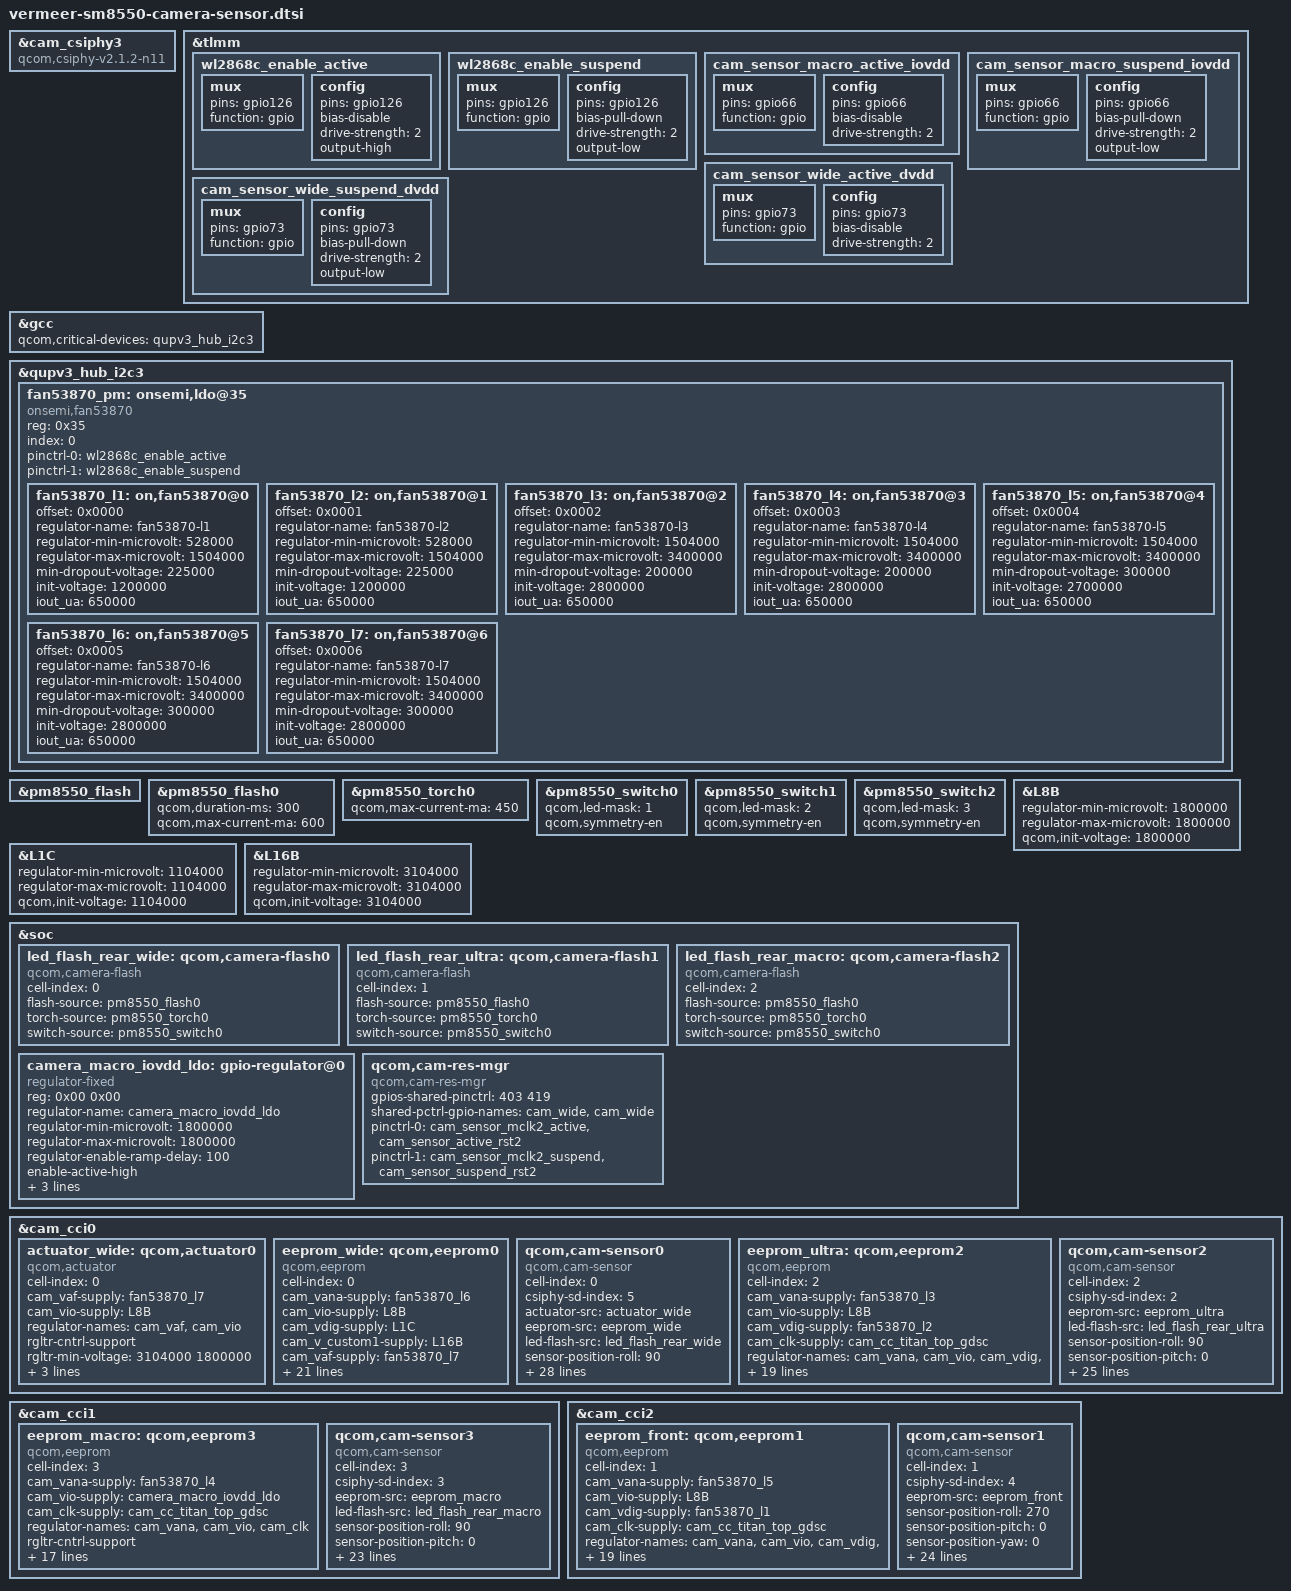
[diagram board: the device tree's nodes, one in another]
#include <dt-bindings/msm-camera.h>

//macro
&cam_csiphy3 {
	compatible = "qcom,csiphy-v2.1.2-n11", "qcom,csiphy";
};

&tlmm {
	wl2868c_enable_active: wl2868c_enable_active {
		mux {
				pins = "gpio126";
				function = "gpio";
		};

		config {
				pins = "gpio126";
				bias-disable;
				drive-strength = <2>;
				output-high;
		};
	};

	wl2868c_enable_suspend: wl2868c_enable_suspend {
		mux {
				pins = "gpio126";
				function = "gpio";
		};

		config {
				pins = "gpio126";
				bias-pull-down;
				drive-strength = <2>;
				output-low;
		};
	};

	cam_sensor_macro_active_iovdd: cam_sensor_macro_active_iovdd {
		mux {
			pins = "gpio66";
			function = "gpio";
		};

		config {
			pins = "gpio66";
			bias-disable; /* No PULL */
			drive-strength = <2>; /* 2 MA */
		};
	};

	cam_sensor_macro_suspend_iovdd: cam_sensor_macro_suspend_iovdd {
		mux {
			pins = "gpio66";
			function = "gpio";
		};

		config {
			pins = "gpio66";
			bias-pull-down; /* PULL DOWN */
			drive-strength = <2>; /* 2 MA */
			output-low;
		};
	};

	cam_sensor_wide_active_dvdd: cam_sensor_wide_active_dvdd {
		mux {
			pins = "gpio73";
			function = "gpio";
		};

		config {
			pins = "gpio73";
			bias-disable; /* No PULL */
			drive-strength = <2>; /* 2 MA */
		};
	};

	cam_sensor_wide_suspend_dvdd: cam_sensor_wide_suspend_dvdd {
		mux {
			pins = "gpio73";
			function = "gpio";
		};

		config {
			pins = "gpio73";
			bias-pull-down; /* PULL DOWN */
			drive-strength = <2>; /* 2 MA */
			output-low;
		};
	};
};

&gcc {
	qcom,critical-devices = <&qupv3_hub_i2c3>;
};

&qupv3_hub_i2c3 {
	#address-cells = <1>;
	#size-cells = <0>;
	status = "ok";

	fan53870_pm:onsemi,ldo@35 {
		compatible = "onsemi,fan53870";
		reg = <0x35>;/*slave address*/
		index = <0>;
		pinctrl-names = "wl2868c_enable", "wl2868c_disable";
		pinctrl-0 = <&wl2868c_enable_active>;
		pinctrl-1 = <&wl2868c_enable_suspend>;

		fan53870_l1:on,fan53870@0{
			offset = /bits/ 16 <0x0000>;
			regulator-name ="fan53870-l1";
			regulator-min-microvolt = <528000>;
			regulator-max-microvolt = <1504000>;
			min-dropout-voltage = <225000>;
			init-voltage = <1200000>;
			iout_ua = <650000>;
		};

		fan53870_l2:on,fan53870@1{
			offset = /bits/ 16 <0x0001>;
			regulator-name ="fan53870-l2";
			regulator-min-microvolt = <528000>;
			regulator-max-microvolt = <1504000>;
			min-dropout-voltage = <225000>;
			init-voltage = <1200000>;
			iout_ua = <650000>;
		};

		fan53870_l3:on,fan53870@2{
			offset = /bits/ 16 <0x0002>;
			regulator-name ="fan53870-l3";
			regulator-min-microvolt = <1504000>;
			regulator-max-microvolt = <3400000>;
			min-dropout-voltage = <200000>;
			init-voltage = <2800000>;
			iout_ua = <650000>;
		};

		fan53870_l4:on,fan53870@3{
			offset = /bits/ 16 <0x0003>;
			regulator-name ="fan53870-l4";
			regulator-min-microvolt = <1504000>;
			regulator-max-microvolt = <3400000>;
			min-dropout-voltage = <200000>;
			init-voltage = <2800000>;
			iout_ua = <650000>;
		};

		fan53870_l5:on,fan53870@4{
			offset = /bits/ 16 <0x0004>;
			regulator-name ="fan53870-l5";
			regulator-min-microvolt = <1504000>;
			regulator-max-microvolt = <3400000>;
			min-dropout-voltage = <300000>;
			init-voltage = <2700000>;
			iout_ua = <650000>;
		};

		fan53870_l6:on,fan53870@5{
			offset = /bits/ 16 <0x0005>;
			regulator-name ="fan53870-l6";
			regulator-min-microvolt = <1504000>;
			regulator-max-microvolt = <3400000>;
			min-dropout-voltage = <300000>;
			init-voltage = <2800000>;
			iout_ua = <650000>;
		};

		fan53870_l7:on,fan53870@6{
			offset = /bits/ 16 <0x0006>;
			regulator-name ="fan53870-l7";
			regulator-min-microvolt = <1504000>;
			regulator-max-microvolt = <3400000>;
			min-dropout-voltage = <300000>;
			init-voltage = <2800000>;
			iout_ua = <650000>;
		};
	};
};

&pm8550_flash {
	status = "ok";
};
&pm8550_flash0 {
	qcom,duration-ms = <300>;
	qcom,max-current-ma = <600>;
};
&pm8550_torch0{
	qcom,max-current-ma = <450>;
};
&pm8550_switch0 {
	qcom,led-mask = <1>;
	qcom,symmetry-en;
};
&pm8550_switch1 {
	qcom,led-mask = <2>;
	qcom,symmetry-en;
};
&pm8550_switch2 {
	qcom,led-mask = <3>;
	qcom,symmetry-en;
};

&L8B {
	regulator-min-microvolt = <1800000>;
	regulator-max-microvolt = <1800000>;
	qcom,init-voltage = <1800000>;
};

&L1C {
	regulator-min-microvolt = <1104000>;
	regulator-max-microvolt = <1104000>;
	qcom,init-voltage = <1104000>;
};

&L16B {
	regulator-min-microvolt = <3104000>;
	regulator-max-microvolt = <3104000>;
	qcom,init-voltage = <3104000>;
};

&soc {
	led_flash_rear_wide: qcom,camera-flash0 {
		cell-index = <0>;
		compatible = "qcom,camera-flash";
		flash-source = <&pm8550_flash0>;
		torch-source = <&pm8550_torch0>;
		switch-source = <&pm8550_switch0>;
		status = "ok";
	};

	led_flash_rear_ultra: qcom,camera-flash1 {
		cell-index = <1>;
		compatible = "qcom,camera-flash";
		flash-source = <&pm8550_flash0>;
		torch-source = <&pm8550_torch0>;
		switch-source = <&pm8550_switch0>;
		status = "ok";
	};

	led_flash_rear_macro: qcom,camera-flash2 {
		cell-index = <2>;
		compatible = "qcom,camera-flash";
		flash-source = <&pm8550_flash0>;
		torch-source = <&pm8550_torch0>;
		switch-source = <&pm8550_switch0>;
		status = "ok";
	};

	camera_macro_iovdd_ldo: gpio-regulator@0 {
		compatible = "regulator-fixed";
		reg = <0x00 0x00>;
		regulator-name = "camera_macro_iovdd_ldo";
		regulator-min-microvolt = <1800000>;
		regulator-max-microvolt = <1800000>;
		regulator-enable-ramp-delay = <100>;
		enable-active-high;
		gpio = <&tlmm 66 0>;
		pinctrl-names = "macro_iovdd_active", "macro_iovdd_suspend";
		pinctrl-0 = <&cam_sensor_macro_active_iovdd
					 &cam_sensor_macro_suspend_iovdd>;
	};
/*P0的bom，下面的LDO没有贴
	camera_wide_dvdd_ldo: gpio-regulator@1 {
		compatible = "regulator-fixed";
		reg = <0x01 0x00>;
		regulator-name = "camera_wide_dvdd_ldo";
		regulator-min-microvolt = <1104000>;
		regulator-max-microvolt = <1104000>;
		regulator-enable-ramp-delay = <100>;
		enable-active-high;
		gpio = <&tlmm 73 0>;
		pinctrl-names = "wide_dvdd_active", "wide_dvdd_suspend";
		pinctrl-0 = <&cam_sensor_wide_active_dvdd
					 &cam_sensor_wide_suspend_dvdd>;
	};
*/
	qcom,cam-res-mgr {
		compatible = "qcom,cam-res-mgr";
		gpios-shared-pinctrl = <403 419>;
		shared-pctrl-gpio-names = "cam_wide", "cam_wide";
		pinctrl-names = "cam_wide_active", "cam_wide_suspend";
		pinctrl-0 = <&cam_sensor_mclk2_active
					 &cam_sensor_active_rst2>;
		pinctrl-1 = <&cam_sensor_mclk2_suspend
					 &cam_sensor_suspend_rst2>;
		status = "ok";
	};
};

&cam_cci0 {

	actuator_wide: qcom,actuator0 {
		cell-index = <0>;
		compatible = "qcom,actuator";
		cam_vaf-supply = <&fan53870_l7>;
		cam_vio-supply = <&L8B>;
		regulator-names = "cam_vaf", "cam_vio";
		rgltr-cntrl-support;
		rgltr-min-voltage = <3104000 1800000>;
		rgltr-max-voltage = <3104000 1800000>;
		rgltr-load-current = <120000 50000>;
		cci-master = <CCI_MASTER_0>;
		status = "ok";
	};

	eeprom_wide: qcom,eeprom0 {
		cell-index = <0>;
		compatible = "qcom,eeprom";
		cam_vana-supply = <&fan53870_l6>;
		cam_vio-supply = <&L8B>;
		cam_vdig-supply = <&L1C>;
		cam_v_custom1-supply = <&L16B>;//apois
		cam_vaf-supply = <&fan53870_l7>;
		cam_clk-supply = <&cam_cc_titan_top_gdsc>;
		regulator-names = "cam_vana", "cam_vio",
			"cam_vdig", "cam_v_custom1", "cam_vaf", "cam_clk";
		rgltr-cntrl-support;
		rgltr-min-voltage = <2800000 1800000 1104000 3104000 3104000 0>;
		rgltr-max-voltage = <2800000 1800000 1104000 3104000 3104000 0>;
		rgltr-load-current = <88000 50000 676300 310000 120000 0>;
		use-shared-clk;
		gpio-no-mux = <0>;
		gpios = <&tlmm 102 0>, <&tlmm 118 0>;
		gpio-reset = <1>;
		gpio-req-tbl-num = <0 1>;
		gpio-req-tbl-flags = <1 0>;
		gpio-req-tbl-label = "CAMIF_MCLK2", "CAM_RESET2";
		cci-master = <CCI_MASTER_0>;
		clocks = <&camcc CAM_CC_MCLK2_CLK>;
		clock-names = "cam_clk";
		clock-cntl-level = "nominal";
		clock-rates = <19200000>;
		status = "ok";
	};

	// wide sensor
	qcom,cam-sensor0 {
		cell-index = <0>;
		compatible = "qcom,cam-sensor";
		csiphy-sd-index = <5>;
		actuator-src = <&actuator_wide>;
		eeprom-src = <&eeprom_wide>;
		led-flash-src = <&led_flash_rear_wide>;
		sensor-position-roll = <90>;
		sensor-position-pitch = <0>;
		sensor-position-yaw = <180>;
		cam_vana-supply = <&fan53870_l6>;
		cam_vio-supply = <&L8B>;//ultra&front also use
		cam_vdig-supply = <&L1C>;//原理图内有两处供电，是基带做了兼容，基带建议使用L1C
		cam_v_custom1-supply = <&L16B>;//apois
		cam_vaf-supply = <&fan53870_l7>;
		cam_clk-supply = <&cam_cc_titan_top_gdsc>;
		regulator-names = "cam_vana", "cam_vio",
			"cam_vdig", "cam_v_custom1", "cam_vaf", "cam_clk";
		rgltr-cntrl-support;
		rgltr-min-voltage = <2800000 1800000 1104000 3104000 3104000 0>;
		rgltr-max-voltage = <2800000 1800000 1104000 3104000 3104000 0>;
		rgltr-load-current = <88000 50000 676300 310000 120000 0>;
		use-shared-clk;
		gpio-no-mux = <0>;
		gpios = <&tlmm 102 0>, <&tlmm 118 0>;
		gpio-reset = <1>;
		gpio-req-tbl-num = <0 1>;
		gpio-req-tbl-flags = <1 0>;
		gpio-req-tbl-label = "CAMIF_MCLK2", "CAM_RESET2";
		cci-master = <CCI_MASTER_0>;
		clocks = <&camcc CAM_CC_MCLK2_CLK>;
		clock-names = "cam_clk";
		clock-cntl-level = "nominal";
		clock-rates = <19200000>;
		status = "ok";
	};

	// Ultra eeprom
	eeprom_ultra: qcom,eeprom2 {
		cell-index = <2>;
		compatible = "qcom,eeprom";
		cam_vana-supply = <&fan53870_l3>;
		cam_vio-supply = <&L8B>;
		cam_vdig-supply = <&fan53870_l2>;
		cam_clk-supply = <&cam_cc_titan_top_gdsc>;
		regulator-names = "cam_vana", "cam_vio", "cam_vdig",
			 "cam_clk";
		rgltr-cntrl-support;
		rgltr-min-voltage = <2700000 1800000 1200000 0>;
		rgltr-max-voltage = <2700000 1800000 1200000 0>;
		rgltr-load-current = <23500 50000 75300 0>;
		gpio-no-mux = <0>;
		pinctrl-names = "cam_default", "cam_suspend";
		pinctrl-0 = <&cam_sensor_mclk1_active
			&cam_sensor_active_rst1>;
		pinctrl-1 = <&cam_sensor_mclk1_suspend
			&cam_sensor_suspend_rst1>;
		gpios = <&tlmm 101 0>, <&tlmm 117 0>;
		gpio-reset = <1>;
		gpio-req-tbl-num = <0 1>;
		gpio-req-tbl-flags = <1 0>;
		gpio-req-tbl-label = "CAMIF_MCLK1", "CAM_RESET1";
		cci-master = <CCI_MASTER_1>;
		clocks = <&camcc CAM_CC_MCLK1_CLK>;
		clock-names = "cam_clk";
		clock-cntl-level = "nominal";
		clock-rates = <19200000>;
		status = "ok";
	};

	// ultra sensor
	qcom,cam-sensor2 {
		cell-index = <2>;
		compatible = "qcom,cam-sensor";
		csiphy-sd-index = <2>;
		eeprom-src = <&eeprom_ultra>;
		led-flash-src = <&led_flash_rear_ultra>;
		sensor-position-roll = <90>;
		sensor-position-pitch = <0>;
		sensor-position-yaw = <180>;
		cam_vana-supply = <&fan53870_l3>;
		cam_vio-supply = <&L8B>;
		cam_vdig-supply = <&fan53870_l2>;
		cam_clk-supply = <&cam_cc_titan_top_gdsc>;
		regulator-names = "cam_vana", "cam_vio", "cam_vdig",
			 "cam_clk";
		rgltr-cntrl-support;
		rgltr-min-voltage = <2700000 1800000 1200000 0>;
		rgltr-max-voltage = <2700000 1800000 1200000 0>;
		rgltr-load-current = <23500 50000 75300 0>;
		gpio-no-mux = <0>;
		pinctrl-names = "cam_default", "cam_suspend";
		pinctrl-0 = <&cam_sensor_mclk1_active
			&cam_sensor_active_rst1>;
		pinctrl-1 = <&cam_sensor_mclk1_suspend
			&cam_sensor_suspend_rst1>;
		gpios = <&tlmm 101 0>, <&tlmm 117 0>;
		gpio-reset = <1>;
		gpio-req-tbl-num = <0 1>;
		gpio-req-tbl-flags = <1 0>;
		gpio-req-tbl-label = "CAMIF_MCLK1", "CAM_RESET1";
		cci-master = <CCI_MASTER_1>;
		clocks = <&camcc CAM_CC_MCLK1_CLK>;
		clock-names = "cam_clk";
		clock-cntl-level = "nominal";
		clock-rates = <19200000>;
		status = "ok";
	};
};

&cam_cci1 {

	// Macro eeprom
	eeprom_macro: qcom,eeprom3 {
		cell-index = <3>;
		compatible = "qcom,eeprom";
		cam_vana-supply = <&fan53870_l4>;
		cam_vio-supply = <&camera_macro_iovdd_ldo>;
		cam_clk-supply = <&cam_cc_titan_top_gdsc>;
		regulator-names = "cam_vana", "cam_vio", "cam_clk";
		rgltr-cntrl-support;
		rgltr-min-voltage = <2800000 1800000 0>;
		rgltr-max-voltage = <2800000 1800000 0>;
		rgltr-load-current = <33000 50000 0>;
		gpio-no-mux = <0>;
		pinctrl-names = "cam_default", "cam_suspend";
		pinctrl-0 = <&cam_sensor_mclk3_active
			&cam_sensor_active_rst3>;
		pinctrl-1 = <&cam_sensor_mclk3_suspend
			&cam_sensor_suspend_rst3>;
		gpios = <&tlmm 103 0>, <&tlmm 119 0>;
		gpio-reset = <1>;
		gpio-req-tbl-num = <0 1>;
		gpio-req-tbl-flags = <1 0>;
		gpio-req-tbl-label = "CAMIF_MCLK3", "CAM_RESET3";
		cci-master = <CCI_MASTER_0>;
		clocks = <&camcc CAM_CC_MCLK3_CLK>;
		clock-names = "cam_clk";
		clock-cntl-level = "nominal";
		clock-rates = <19200000>;
		status = "ok";
	};
	// macro sensor
	qcom,cam-sensor3 {
		cell-index = <3>;
		compatible = "qcom,cam-sensor";
		csiphy-sd-index = <3>;
		eeprom-src = <&eeprom_macro>;
		led-flash-src = <&led_flash_rear_macro>;
		sensor-position-roll = <90>;
		sensor-position-pitch = <0>;
		sensor-position-yaw = <180>;
		cam_vana-supply = <&fan53870_l4>;
		cam_vio-supply = <&camera_macro_iovdd_ldo>;
		cam_clk-supply = <&cam_cc_titan_top_gdsc>;
		regulator-names = "cam_vana", "cam_vio", "cam_clk";
		rgltr-cntrl-support;
		rgltr-min-voltage = <2800000 1800000 0>;
		rgltr-max-voltage = <2800000 1800000 0>;
		rgltr-load-current = <33000 50000 0>;
		gpio-no-mux = <0>;
		pinctrl-names = "cam_default", "cam_suspend";
		pinctrl-0 = <&cam_sensor_mclk3_active
			&cam_sensor_active_rst3>;
		pinctrl-1 = <&cam_sensor_mclk3_suspend
			&cam_sensor_suspend_rst3>;
		gpios = <&tlmm 103 0>, <&tlmm 119 0>;
		gpio-reset = <1>;
		gpio-req-tbl-num = <0 1>;
		gpio-req-tbl-flags = <1 0>;
		gpio-req-tbl-label = "CAMIF_MCLK3", "CAM_RESET3";
		cci-master = <CCI_MASTER_0>;
		clocks = <&camcc CAM_CC_MCLK3_CLK>;
		clock-names = "cam_clk";
		clock-cntl-level = "nominal";
		clock-rates = <19200000>;
		status = "ok";
	};
};

&cam_cci2 {
	// front eeprom
	eeprom_front: qcom,eeprom1 {
		cell-index = <1>;
		compatible = "qcom,eeprom";
		cam_vana-supply = <&fan53870_l5>;
		cam_vio-supply = <&L8B>;
		cam_vdig-supply = <&fan53870_l1>;
		cam_clk-supply = <&cam_cc_titan_top_gdsc>;
		regulator-names = "cam_vana", "cam_vio", "cam_vdig",
			"cam_clk";
		rgltr-cntrl-support;
		rgltr-min-voltage = <2800000 1800000 1200000 0>;
		rgltr-max-voltage = <2800000 1800000 1200000 0>;
		rgltr-load-current = <50000 50000 105000 0>;
		gpio-no-mux = <0>;
		pinctrl-names = "cam_default", "cam_suspend";
		pinctrl-0 = <&cam_sensor_mclk0_active
			&cam_sensor_active_rst4>;
		pinctrl-1 = <&cam_sensor_mclk0_suspend
			&cam_sensor_suspend_rst4>;
		gpios = <&tlmm 100 0>, <&tlmm 120 0>;
		gpio-reset = <1>;
		gpio-req-tbl-num = <0 1>;
		gpio-req-tbl-flags = <1 0>;
		gpio-req-tbl-label = "CAMIF_MCLK0", "CAM_RESET4";
		cci-master = <CCI_MASTER_0>;
		clocks = <&camcc CAM_CC_MCLK0_CLK>;
		clock-names = "cam_clk";
		clock-cntl-level = "nominal";
		clock-rates = <19200000>;
		status = "ok";
	};

	// front sensor
	qcom,cam-sensor1 {
		cell-index = <1>;
		compatible = "qcom,cam-sensor";
		csiphy-sd-index = <4>;
		eeprom-src = <&eeprom_front>;
		sensor-position-roll = <270>;
		sensor-position-pitch = <0>;
		sensor-position-yaw = <0>;
		cam_vana-supply = <&fan53870_l5>;
		cam_vio-supply = <&L8B>;
		cam_vdig-supply = <&fan53870_l1>;
		cam_clk-supply = <&cam_cc_titan_top_gdsc>;
		regulator-names = "cam_vana", "cam_vio", "cam_vdig",
			"cam_clk";
		rgltr-cntrl-support;
		rgltr-min-voltage = <2800000 1800000 1200000 0>;
		rgltr-max-voltage = <2800000 1800000 1200000 0>;
		rgltr-load-current = <50000 50000 105000 0>;
		gpio-no-mux = <0>;
		pinctrl-names = "cam_default", "cam_suspend";
		pinctrl-0 = <&cam_sensor_mclk0_active
			&cam_sensor_active_rst4>;
		pinctrl-1 = <&cam_sensor_mclk0_suspend
			&cam_sensor_suspend_rst4>;
		gpios = <&tlmm 100 0>, <&tlmm 120 0>;
		gpio-reset = <1>;
		gpio-req-tbl-num = <0 1>;
		gpio-req-tbl-flags = <1 0>;
		gpio-req-tbl-label = "CAMIF_MCLK0", "CAM_RESET4";
		cci-master = <CCI_MASTER_0>;
		clocks = <&camcc CAM_CC_MCLK0_CLK>;
		clock-names = "cam_clk";
		clock-cntl-level = "nominal";
		clock-rates = <19200000>;
		status = "ok";
	};
};
